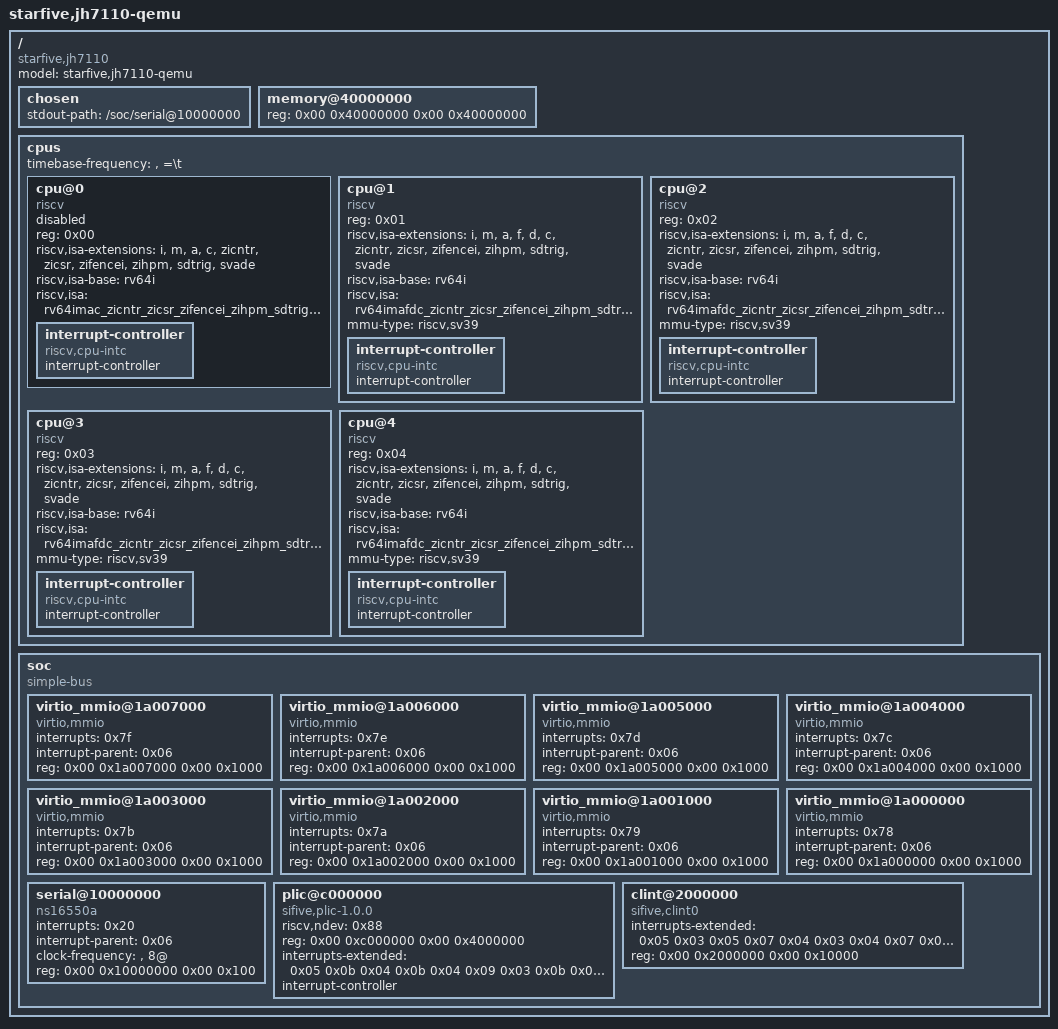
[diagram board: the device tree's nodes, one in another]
/dts-v1/;

/ {
	#address-cells = <0x02>;
	#size-cells = <0x02>;
	compatible = "starfive,jh7110";
	model = "starfive,jh7110-qemu";

	chosen {
		stdout-path = "/soc/serial@10000000";
	};

	memory@40000000 {
		device_type = "memory";
		reg = <0x00 0x40000000 0x00 0x40000000>;
	};

	cpus {
		#address-cells = <0x01>;
		#size-cells = <0x00>;
		timebase-frequency = "", "=\t";

		cpu@0 {
			device_type = "cpu";
			reg = <0x00>;
			compatible = "riscv";
			status = "disabled";
			riscv,isa-extensions = "i", "m", "a", "c", "zicntr", "zicsr", "zifencei", "zihpm", "sdtrig", "svade";
			riscv,isa-base = "rv64i";
			riscv,isa = "rv64imac_zicntr_zicsr_zifencei_zihpm_sdtrig_svade";

			interrupt-controller {
				phandle = <0x05>;
				compatible = "riscv,cpu-intc";
				interrupt-controller;
				#interrupt-cells = <0x01>;
			};
		};

		cpu@1 {
			device_type = "cpu";
			reg = <0x01>;
			compatible = "riscv";
			status = "okay";
			riscv,isa-extensions = "i", "m", "a", "f", "d", "c", "zicntr", "zicsr", "zifencei", "zihpm", "sdtrig", "svade";
			riscv,isa-base = "rv64i";
			riscv,isa = "rv64imafdc_zicntr_zicsr_zifencei_zihpm_sdtrig_svade";
			mmu-type = "riscv,sv39";

			interrupt-controller {
				phandle = <0x04>;
				compatible = "riscv,cpu-intc";
				interrupt-controller;
				#interrupt-cells = <0x01>;
			};
		};

		cpu@2 {
			device_type = "cpu";
			reg = <0x02>;
			compatible = "riscv";
			status = "okay";
			riscv,isa-extensions = "i", "m", "a", "f", "d", "c", "zicntr", "zicsr", "zifencei", "zihpm", "sdtrig", "svade";
			riscv,isa-base = "rv64i";
			riscv,isa = "rv64imafdc_zicntr_zicsr_zifencei_zihpm_sdtrig_svade";
			mmu-type = "riscv,sv39";

			interrupt-controller {
				phandle = <0x03>;
				compatible = "riscv,cpu-intc";
				interrupt-controller;
				#interrupt-cells = <0x01>;
			};
		};

		cpu@3 {
			device_type = "cpu";
			reg = <0x03>;
			compatible = "riscv";
			status = "okay";
			riscv,isa-extensions = "i", "m", "a", "f", "d", "c", "zicntr", "zicsr", "zifencei", "zihpm", "sdtrig", "svade";
			riscv,isa-base = "rv64i";
			riscv,isa = "rv64imafdc_zicntr_zicsr_zifencei_zihpm_sdtrig_svade";
			mmu-type = "riscv,sv39";

			interrupt-controller {
				phandle = <0x02>;
				compatible = "riscv,cpu-intc";
				interrupt-controller;
				#interrupt-cells = <0x01>;
			};
		};

		cpu@4 {
			device_type = "cpu";
			reg = <0x04>;
			compatible = "riscv";
			status = "okay";
			riscv,isa-extensions = "i", "m", "a", "f", "d", "c", "zicntr", "zicsr", "zifencei", "zihpm", "sdtrig", "svade";
			riscv,isa-base = "rv64i";
			riscv,isa = "rv64imafdc_zicntr_zicsr_zifencei_zihpm_sdtrig_svade";
			mmu-type = "riscv,sv39";

			interrupt-controller {
				phandle = <0x01>;
				compatible = "riscv,cpu-intc";
				interrupt-controller;
				#interrupt-cells = <0x01>;
			};
		};
	};

	soc {
		#address-cells = <0x02>;
		#size-cells = <0x02>;
		compatible = "simple-bus";
		ranges;

		virtio_mmio@1a007000 {
			interrupts = <0x7f>;
			interrupt-parent = <0x06>;
			reg = <0x00 0x1a007000 0x00 0x1000>;
			compatible = "virtio,mmio";
		};

		virtio_mmio@1a006000 {
			interrupts = <0x7e>;
			interrupt-parent = <0x06>;
			reg = <0x00 0x1a006000 0x00 0x1000>;
			compatible = "virtio,mmio";
		};

		virtio_mmio@1a005000 {
			interrupts = <0x7d>;
			interrupt-parent = <0x06>;
			reg = <0x00 0x1a005000 0x00 0x1000>;
			compatible = "virtio,mmio";
		};

		virtio_mmio@1a004000 {
			interrupts = <0x7c>;
			interrupt-parent = <0x06>;
			reg = <0x00 0x1a004000 0x00 0x1000>;
			compatible = "virtio,mmio";
		};

		virtio_mmio@1a003000 {
			interrupts = <0x7b>;
			interrupt-parent = <0x06>;
			reg = <0x00 0x1a003000 0x00 0x1000>;
			compatible = "virtio,mmio";
		};

		virtio_mmio@1a002000 {
			interrupts = <0x7a>;
			interrupt-parent = <0x06>;
			reg = <0x00 0x1a002000 0x00 0x1000>;
			compatible = "virtio,mmio";
		};

		virtio_mmio@1a001000 {
			interrupts = <0x79>;
			interrupt-parent = <0x06>;
			reg = <0x00 0x1a001000 0x00 0x1000>;
			compatible = "virtio,mmio";
		};

		virtio_mmio@1a000000 {
			interrupts = <0x78>;
			interrupt-parent = <0x06>;
			reg = <0x00 0x1a000000 0x00 0x1000>;
			compatible = "virtio,mmio";
		};

		serial@10000000 {
			interrupts = <0x20>;
			interrupt-parent = <0x06>;
			clock-frequency = "", "8@";
			reg = <0x00 0x10000000 0x00 0x100>;
			compatible = "ns16550a";
		};

		plic@c000000 {
			phandle = <0x06>;
			riscv,ndev = <0x88>;
			reg = <0x00 0xc000000 0x00 0x4000000>;
			interrupts-extended = <0x05 0x0b 0x04 0x0b 0x04 0x09 0x03 0x0b 0x03 0x09 0x02 0x0b 0x02 0x09 0x01 0x0b 0x01 0x09>;
			interrupt-controller;
			compatible = "sifive,plic-1.0.0", "riscv,plic0";
			#interrupt-cells = <0x01>;
			#address-cells = <0x00>;
		};

		clint@2000000 {
			interrupts-extended = <0x05 0x03 0x05 0x07 0x04 0x03 0x04 0x07 0x03 0x03 0x03 0x07 0x02 0x03 0x02 0x07 0x01 0x03 0x01 0x07>;
			reg = <0x00 0x2000000 0x00 0x10000>;
			compatible = "sifive,clint0", "riscv,clint0";
		};
	};
};
